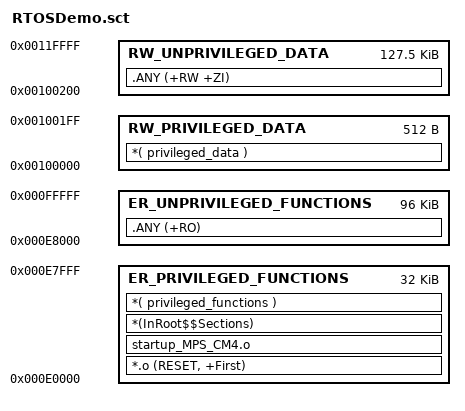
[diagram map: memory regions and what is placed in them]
; *************************************************************
; *** Scatter-Loading Description File generated by uVision ***
; *************************************************************


LR_IROM1 0xE0000 0x40000  ; load region size_region
{
	ER_PRIVILEGED_FUNCTIONS 0xE0000 0x8000  {
		*.o (RESET, +First)
		startup_MPS_CM4.o
		*(InRoot$$Sections)
		*( privileged_functions )
	}

	ER_UNPRIVILEGED_FUNCTIONS 0xE8000 0x18000 {
		.ANY (+RO)
	}

	RW_PRIVILEGED_DATA 0x100000 0x200 {
		*( privileged_data )
	}

	RW_UNPRIVILEGED_DATA 0x100200 0x1FE00 {
		.ANY (+RW +ZI)
	}
}



